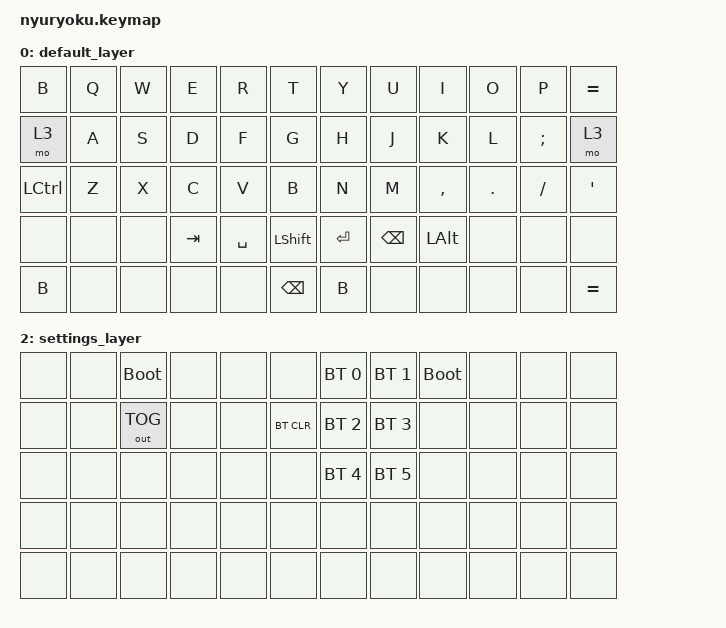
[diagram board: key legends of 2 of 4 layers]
/*
 * Copyright (c) 2021 The ZMK Contributors
 *
 * SPDX-License-Identifier: MIT
 */

#include <behaviors.dtsi>
#include <dt-bindings/zmk/keys.h>
#include <dt-bindings/zmk/bt.h>
#include <dt-bindings/zmk/outputs.h>
#define BASE 0
#define NUMPAD 1
#define KBS 2
#define OTHERKEYS 3

/ {
    behaviors {
        skq: sticky_key_quick_release {
            compatible = "zmk,behavior-sticky-key";
            #binding-cells = <1>;
            bindings = <&kp>;
            release-after-ms = <1000>;
            quick-release;
            ignore-modifiers;
        };
        td0: capitalization_tap_dance {
            compatible = "zmk,behavior-tap-dance";
            #binding-cells = <0>;
            tapping-term-ms = <200>;
            bindings = <&skq LSHFT>, <&kp CLCK>;
        };
        lse0: layerSwitchEncoder {
            compatible = "zmk,behavior-sensor-rotate-var";
            #sensor-binding-cells = <2>;
            bindings = <&to>, <&to>;
        };
    };
    combos {
        compatible = "zmk,combos";
        combo_equal {
            timeout-ms = <200>;
            key-positions = <30 27 10>;
            bindings = <&kp EQUAL>;
            layers = <0>;
        };
        combo_plus {
            timeout-ms = <200>;
            key-positions = <31 4 10 13>;
            bindings = <&kp LPAR>;
            layers = <0>;
        };
        combo_forwardsqrbracket {
            timeout-ms = <200>;
            key-positions = <6 13 27 31>;
            bindings = <&kp LBKT>;
            layers = <0>;
        };
        combo_backwardsqrbracket {
            timeout-ms = <200>;
            key-positions = <31 13 27 31>;
            bindings = <&kp RBKT>;
            layers = <0>;
        };
        combo_asterisk {
            timeout-ms = <200>;
            key-positions = <30 13 9>;
            bindings = <&kp STAR>;
            layers = <0>;
        };
        combo_exclamation {
            timeout-ms = <200>;
            key-positions = <30 8 10>;
            bindings = <&kp EXCL>;
            layers = <0>;
        };
        combo_at {
            timeout-ms = <200>;
            key-positions = <30 12 19>;
            bindings = <&kp AT>;
            layers = <0>;
        };
        combo_hash {
            timeout-ms = <200>;
            key-positions = <30 18 12 13 18>;
            bindings = <&kp HASH>;
            layers = <0>;
        };
        combo_percent {
            timeout-ms = <200>;
            key-positions = <30 4 9 8 19>;
            bindings = <&kp PERCENT>;
            layers = <0>;
        };
        combo_dollar {
            timeout-ms = <200>;
            key-positions = <30 14 10 10 9>;
            bindings = <&kp DOLLAR>;
            layers = <0>;
        };
        combo_caret {
            timeout-ms = <200>;
            key-positions = <30 7 9 19>;
            bindings = <&kp CARET>;
            layers = <0>;
        };
        combo_forwardparanthesis {
            timeout-ms = <200>;
            key-positions = <30 10 4 9 19 18>;
            bindings = <&kp LPAR>;
            layers = <0>;
        };
        combo_backwardparanthesis {
            timeout-ms = <200>;
            key-positions = <30 9 4 9 19 18>;
            bindings = <&kp LPAR>;
            layers = <0>;
        };
        combo_question {
            timeout-ms = <200>;
            key-positions = <30 27 13 19>;
            bindings = <&kp QMARK>;
            layers = <0>;
        };
        combo_forwardbrace {
            timeout-ms = <200>;
            key-positions = <30 6 31 9 8>;
            bindings = <&kp LBRC>;
            layers = <0>;
        };
        combo_backwardbrace {
            timeout-ms = <200>;
            key-positions = <30 31 31 9 8>;
            bindings = <&kp RBRC>;
            layers = <0>;
        };
        combo_tilde {
            timeout-ms = <200>;
            key-positions = <30 19 10 17>;
            bindings = <&kp TILDE>;
            layers = <0>;
        };
    };

    keymap {
        compatible = "zmk,keymap";

        default_layer {
            bindings = <
                &kp B       &kp Q      &kp W      &kp E      &kp R      &kp T            &kp Y      &kp U      &kp I      &kp O      &kp P       &kp EQUAL
                &mo 3       &kp A      &kp S      &kp D      &kp F      &kp G            &kp H      &kp J      &kp K      &kp L      &kp SEMI    &mo 3
                &kp LCTRL   &kp Z      &kp X      &kp C      &kp V      &kp B            &kp N      &kp M      &kp COMMA  &kp PERIOD &kp FSLH    &kp APOS
                &none       &none      &none      &kp TAB    &kp SPACE  &kp LSHIFT       &kp ENTER  &kp BSPC   &kp LALT   &none      &none       &none
                &kp B       &none      &none      &none      &none      &kp BSPC         &kp B      &none      &none      &none      &none       &kp EQUAL
            >;
            sensor-bindings = <&lse0 0 1 &inc_dec_kp C_VOL_UP C_VOL_DN &lse0 0 1 &inc_dec_kp C_PLAY C_PAUSE>;
        };
        numpad_function_layer {
            bindings = <
                &kp B     &none      &kp N7     &kp N8      &kp N9     &none            &kp F1      &kp F2      &kp F3      &kp F4      &kp F5     &kp EQUAL
                &none     &none      &kp N4     &kp N5      &kp N6     &kp N0           &kp F6      &kp F7      &kp F8      &kp F9      &kp F10    &kp BSLH
                &kp LALT  &none      &kp N1     &kp N2      &kp N3     &none            &kp F11     &kp F12     &none       &kp RALT    &kp TAB    &kp RCTRL
                &none     &none      &none      &kp TAB     &kp SPACE  &kp LSHIFT       &kp ENTER   &kp BSPC    &kp SPACE   &none       &none      &none
                &kp B                                               &kp B            &kp B                                                      &kp EQUAL
            >;
            sensor-bindings = <&lse0 0 2 &inc_dec_kp C_VOL_UP C_VOL_DN &lse0 0 2 &inc_dec_kp C_PLAY C_PAUSE>;
        };
        settings_layer {
            bindings = <
                &none      &none      &bootloader  &none      &none     &none            &bt BT_SEL 0      &bt BT_SEL 1      &bootloader &none      &none       &none
                &none      &none      &out OUT_TOG &none      &none     &bt BT_CLR       &bt BT_SEL 2      &bt BT_SEL 3      &none       &none      &none       &none
                &none      &none      &none        &none      &none     &none            &bt BT_SEL 4      &bt BT_SEL 5      &none       &none      &none       &none
                &none      &none      &none        &none      &none     &none            &none             &none             &none       &none      &none       &none
                &none      &none      &none        &none      &none     &none            &none             &none             &none       &none      &none       &none
            >;
            sensor-bindings = <&lse0 1 2 &inc_dec_kp C_VOL_UP C_VOL_DN &lse0 1 2 &inc_dec_kp C_PLAY C_PAUSE>;
        };
        otherkeys {
            bindings = <
                &kp B       &kp ESC         &kp HASH   &kp AT     &kp DLLR  &kp PRCNT       &kp TILDE   &kp F2      &kp F3      &kp F4      &kp F5          &kp EQUAL
                &none       &kp LBRC        &kp RBRC   &kp LPAR   &kp RPAR  &kp STAR        &kp F6      &kp F7      &kp F8      &kp F9      &kp F10         &none
                &bootloader &studio_unlock  &kp CARET  &kp AMPS   &kp GRAVE &kp EXCL        &kp F11     &kp F12     &none       &kp RALT    &studio_unlock  &bootloader
                &none       &none           &none      &kp TAB    &kp BSPC  &td0            &kp ENTER   &kp SPACE   &kp ESC     &none       &none           &none
                &kp B                                                  &kp B           &kp B                                                                &kp EQUAL
            >;
            sensor-bindings = <&lse0 0 1 &inc_dec_kp C_VOL_UP C_VOL_DN &lse0 0 1 &inc_dec_kp C_PLAY C_PAUSE>;
        };
    };
};
